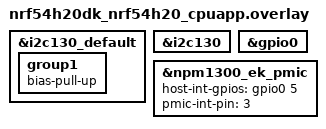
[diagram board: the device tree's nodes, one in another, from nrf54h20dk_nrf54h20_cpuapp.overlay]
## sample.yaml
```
# Copyright (c) 2023 Nordic Semiconductor ASA
# SPDX-License-Identifier: LicenseRef-Nordic-5-Clause
sample:
  name: nPM1300 fuel gauge

common:
  integration_platforms:
    - nrf52dk/nrf52832
    - nrf52840dk/nrf52840
    - nrf5340dk/nrf5340/cpuapp
    - nrf54l15dk/nrf54l15/cpuapp
    - nrf54h20dk/nrf54h20/cpuapp
    - nrf9160dk/nrf9160
  platform_allow:
    - nrf52dk/nrf52832
    - nrf52840dk/nrf52840
    - nrf5340dk/nrf5340/cpuapp
    - nrf54l15dk/nrf54l15/cpuapp
    - nrf54h20dk/nrf54h20/cpuapp
    - nrf9160dk/nrf9160
  tags: pmic ci_samples_pmic

tests:
  samples.npm1300_fuel_gauge:
    sysbuild: true
    platform_allow: nrf52dk/nrf52832 nrf52840dk/nrf52840 nrf5340dk/nrf5340/cpuapp
    harness: console
    tags: sysbuild
    harness_config:
      fixture: nPM1300_setup_eng_b
      type: multi_line
      ordered: true
      regex:
        - "PMIC device ok"
        - "V: [0-9.]+, I: [0-9.-]+, T: [0-9.-]+"
        - "SoC: [0-9.]+, TTE: ([0-9.]+|nan), TTF: ([0-9.]+|nan)"
  samples.compile:
    sysbuild: true
    platform_allow: nrf9160dk/nrf9160 nrf54l15dk/nrf54l15/cpuapp nrf54h20dk/nrf54h20/cpuapp
    harness: shield
    tags: shield sysbuild ci_samples_pmic
    extra_args: SHIELD=npm1300_ek
```

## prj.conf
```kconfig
# Copyright (c) 2023 Nordic Semiconductor ASA
# SPDX-License-Identifier: LicenseRef-Nordic-5-Clause

CONFIG_SHELL=y
CONFIG_LOG=y
CONFIG_LOG_CMDS=y
CONFIG_GPIO=y
CONFIG_REGULATOR=y
CONFIG_SENSOR=y
CONFIG_I2C_SHELL=y
CONFIG_NRF_FUEL_GAUGE=y
CONFIG_REQUIRES_FLOAT_PRINTF=y
CONFIG_MAIN_STACK_SIZE=1536
```

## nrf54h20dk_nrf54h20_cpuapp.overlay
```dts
/*
 * Copyright (c) 2024 Nordic Semiconductor ASA
 *
 * SPDX-License-Identifier: LicenseRef-Nordic-5-Clause
 */

 #include <dt-bindings/regulator/npm1300.h>

&i2c130_default {
	group1 {
		bias-pull-up;
	};
};

&i2c130 {
	status = "okay";
};

&gpio0 {
	status = "okay";
};

&npm1300_ek_pmic {
	host-int-gpios = <&gpio0 5 0>;
	pmic-int-pin = <3>;
};
```

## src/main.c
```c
/*
 * Copyright (c) 2023 Nordic Semiconductor ASA
 * SPDX-License-Identifier: LicenseRef-Nordic-5-Clause
 */

#include <stdlib.h>

#include <zephyr/kernel.h>
#include <zephyr/device.h>
#include <zephyr/drivers/gpio.h>
#include <zephyr/drivers/mfd/npm1300.h>
#include <zephyr/drivers/sensor.h>
#include <zephyr/sys/printk.h>

#include "fuel_gauge.h"

#define SLEEP_TIME_MS 1000

static const struct device *pmic = DEVICE_DT_GET(DT_NODELABEL(npm1300_ek_pmic));
static const struct device *charger = DEVICE_DT_GET(DT_NODELABEL(npm1300_ek_charger));
static volatile bool vbus_connected;

static void event_callback(const struct device *dev, struct gpio_callback *cb, uint32_t pins)
{
	if (pins & BIT(NPM1300_EVENT_VBUS_DETECTED)) {
		printk("Vbus connected\n");
		vbus_connected = true;
	}

	if (pins & BIT(NPM1300_EVENT_VBUS_REMOVED)) {
		printk("Vbus removed\n");
		vbus_connected = false;
	}
}

int main(void)
{
	int err;

	if (!device_is_ready(pmic)) {
		printk("Pmic device not ready.\n");
		return 0;
	}

	if (!device_is_ready(charger)) {
		printk("Charger device not ready.\n");
		return 0;
	}

	if (fuel_gauge_init(charger) < 0) {
		printk("Could not initialise fuel gauge.\n");
		return 0;
	}

	static struct gpio_callback event_cb;

	gpio_init_callback(&event_cb, event_callback,
				   BIT(NPM1300_EVENT_VBUS_DETECTED) |
				   BIT(NPM1300_EVENT_VBUS_REMOVED));

	err = mfd_npm1300_add_callback(pmic, &event_cb);
	if (err) {
		printk("Failed to add pmic callback.\n");
		return 0;
	}

	/* Initialise vbus detection status. */
	struct sensor_value val;
	int ret = sensor_attr_get(charger, SENSOR_CHAN_CURRENT, SENSOR_ATTR_UPPER_THRESH, &val);

	if (ret < 0) {
		return false;
	}

	vbus_connected = (val.val1 != 0) || (val.val2 != 0);

	printk("PMIC device ok\n");

	while (1) {
		fuel_gauge_update(charger, vbus_connected);
		k_msleep(SLEEP_TIME_MS);
	}
}
```

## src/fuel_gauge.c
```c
/*
 * Copyright (c) 2023 Nordic Semiconductor ASA
 * SPDX-License-Identifier: LicenseRef-Nordic-5-Clause
 */

#include <stdlib.h>

#include <zephyr/kernel.h>
#include <zephyr/device.h>
#include <zephyr/drivers/sensor.h>
#include <zephyr/drivers/sensor/npm1300_charger.h>
#include <zephyr/sys/printk.h>
#include <zephyr/sys/util.h>

#include "nrf_fuel_gauge.h"

/* nPM1300 CHARGER.BCHGCHARGESTATUS.CONSTANTCURRENT register bitmask */
#define NPM1300_CHG_STATUS_CC_MASK BIT(3)

static float max_charge_current;
static float term_charge_current;
static int64_t ref_time;

static const struct battery_model battery_model = {
#include "battery_model.inc"
};

static int read_sensors(const struct device *charger,
	float *voltage, float *current, float *temp, int32_t *chg_status)
{
	struct sensor_value value;
	int ret;

	ret = sensor_sample_fetch(charger);
	if (ret < 0) {
		return ret;
	}

	sensor_channel_get(charger, SENSOR_CHAN_GAUGE_VOLTAGE, &value);
	*voltage = (float)value.val1 + ((float)value.val2 / 1000000);

	sensor_channel_get(charger, SENSOR_CHAN_GAUGE_TEMP, &value);
	*temp = (float)value.val1 + ((float)value.val2 / 1000000);

	sensor_channel_get(charger, SENSOR_CHAN_GAUGE_AVG_CURRENT, &value);
	*current = (float)value.val1 + ((float)value.val2 / 1000000);

	sensor_channel_get(charger, SENSOR_CHAN_NPM1300_CHARGER_STATUS, &value);
	*chg_status = value.val1;

	return 0;
}

int fuel_gauge_init(const struct device *charger)
{
	struct sensor_value value;
	struct nrf_fuel_gauge_init_parameters parameters = {
		.model = &battery_model,
		.opt_params = NULL,
	};
	int32_t chg_status;
	int ret;

	printk("nRF Fuel Gauge version: %s\n", nrf_fuel_gauge_version);

	ret = read_sensors(charger, &parameters.v0, &parameters.i0, &parameters.t0, &chg_status);
	if (ret < 0) {
		return ret;
	}

	/* Store charge nominal and termination current, needed for ttf calculation */
	sensor_channel_get(charger, SENSOR_CHAN_GAUGE_DESIRED_CHARGING_CURRENT, &value);
	max_charge_current = (float)value.val1 + ((float)value.val2 / 1000000);
	term_charge_current = max_charge_current / 10.f;

	nrf_fuel_gauge_init(&parameters, NULL);

	ref_time = k_uptime_get();

	return 0;
}

int fuel_gauge_update(const struct device *charger, bool vbus_connected)
{
	float voltage;
	float current;
	float temp;
	float soc;
	float tte;
	float ttf;
	float delta;
	int32_t chg_status;
	bool cc_charging;
	int ret;

	ret = read_sensors(charger, &voltage, &current, &temp, &chg_status);
	if (ret < 0) {
		printk("Error: Could not read from charger device\n");
		return ret;
	}

	cc_charging = (chg_status & NPM1300_CHG_STATUS_CC_MASK) != 0;

	delta = (float) k_uptime_delta(&ref_time) / 1000.f;

	soc = nrf_fuel_gauge_process(voltage, current, temp, delta, vbus_connected, NULL);
	tte = nrf_fuel_gauge_tte_get();
	ttf = nrf_fuel_gauge_ttf_get(cc_charging, -term_charge_current);

	printk("V: %.3f, I: %.3f, T: %.2f, ", (double)voltage, (double)current, (double)temp);
	printk("SoC: %.2f, TTE: %.0f, TTF: %.0f\n", (double)soc, (double)tte, (double)ttf);

	return 0;
}
```
